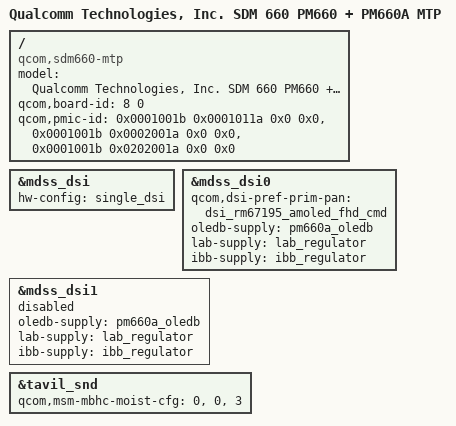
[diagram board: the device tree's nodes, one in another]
/dts-v1/;

#include "sdm660.dtsi"
#include "sdm660-mtp.dtsi"
#include "msm-pm660a.dtsi"
#include "sdm660-external-codec.dtsi"

/ {
	model = "Qualcomm Technologies, Inc. SDM 660 PM660 + PM660A MTP";
	compatible = "qcom,sdm660-mtp", "qcom,sdm660", "qcom,mtp";
	qcom,board-id = <8 0>;
	qcom,pmic-id = <0x0001001b 0x0001011a 0x0 0x0>,
			<0x0001001b 0x0002001a 0x0 0x0>,
			<0x0001001b 0x0202001a 0x0 0x0>;
};

&mdss_dsi {
	hw-config = "single_dsi";
};

&mdss_dsi0 {
	qcom,dsi-pref-prim-pan = <&dsi_rm67195_amoled_fhd_cmd>;
	oledb-supply = <&pm660a_oledb>;
	lab-supply = <&lab_regulator>;
	ibb-supply = <&ibb_regulator>;
};

&mdss_dsi1 {
	status = "disabled";
	oledb-supply = <&pm660a_oledb>;
	lab-supply = <&lab_regulator>;
	ibb-supply = <&ibb_regulator>;
};

&tavil_snd {
	qcom,msm-mbhc-moist-cfg = <0>, <0>, <3>;
};
